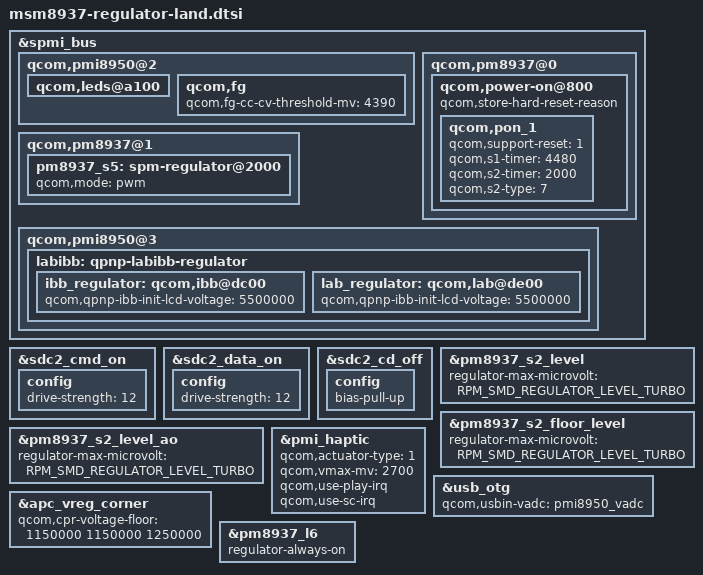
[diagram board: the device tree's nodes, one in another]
&spmi_bus {
	qcom,pmi8950@2 {
		qcom,leds@a100 {
			/delete-property/status;
			/delete-node/ qcom,led_mpp_2;
		};

		qcom,fg {
			qcom,fg-cc-cv-threshold-mv = <4390>;
		};
	};

	qcom,pm8937@0 {
		qcom,power-on@800 {
			qcom,store-hard-reset-reason;
			qcom,pon_1 {
				qcom,support-reset = <1>;
                                qcom,s1-timer = <4480>;
				qcom,s2-timer = <2000>;
				qcom,s2-type = <7>;
			};
		};
	};

	qcom,pm8937@1 {
		pm8937_s5: spm-regulator@2000 {
			qcom,mode = "pwm";
		};
	};

	qcom,pmi8950@3 {
		labibb: qpnp-labibb-regulator {
			ibb_regulator: qcom,ibb@dc00 {
				/delete-property/
					qcom,qpnp-ibb-use-default-voltage;
				qcom,qpnp-ibb-init-lcd-voltage = <5500000>;
			};

			lab_regulator: qcom,lab@de00 {
				/delete-property/
					qcom,qpnp-ibb-use-default-voltage;
				qcom,qpnp-ibb-init-lcd-voltage = <5500000>;
			};
		};
	};
};

&sdc2_cmd_on {
	config {
		drive-strength = <12>;
	};
};

&sdc2_data_on {
	config {
		drive-strength = <12>;
	};
};

&sdc2_cd_off {
	config {
		/delete-property/ bias-disable;
		bias-pull-up;
	};
};

&pm8937_s2_level {
	regulator-max-microvolt =
		<RPM_SMD_REGULATOR_LEVEL_TURBO>;
};

&pm8937_s2_floor_level {
	regulator-max-microvolt =
		<RPM_SMD_REGULATOR_LEVEL_TURBO>;
};

&pm8937_s2_level_ao {
	regulator-max-microvolt =
		<RPM_SMD_REGULATOR_LEVEL_TURBO>;
};

&pmi_haptic {
	qcom,actuator-type = <1>;
	qcom,vmax-mv = <2700>;
	qcom,use-play-irq;
	qcom,use-sc-irq;
};

&usb_otg {
	qcom,usbin-vadc = <&pmi8950_vadc>;
};

&apc_vreg_corner {
	qcom,cpr-voltage-floor = <1150000 1150000 1250000>;
	/delete-property/ qcom.cpr-enable;
};

&pm8937_l6 {
	regulator-always-on;
};
